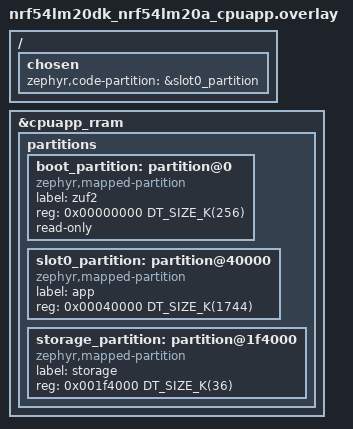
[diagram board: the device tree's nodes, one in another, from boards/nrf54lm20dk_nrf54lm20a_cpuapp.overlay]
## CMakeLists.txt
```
cmake_minimum_required(VERSION 3.20.0)

find_package(Zephyr REQUIRED HINTS $ENV{ZEPHYR_BASE})
project(zuf2_hello)

target_sources(app PRIVATE src/main.c)
```

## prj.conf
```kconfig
CONFIG_USE_DT_CODE_PARTITION=y
CONFIG_INIT_ARCH_HW_AT_BOOT=y
CONFIG_BOOT_BANNER=y

CONFIG_LOG=y
CONFIG_GPIO=y
CONFIG_MAIN_STACK_SIZE=2048
```

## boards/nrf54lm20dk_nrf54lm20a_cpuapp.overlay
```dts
/delete-node/ &boot_partition;
/delete-node/ &slot0_partition;
/delete-node/ &slot1_partition;
/delete-node/ &storage_partition;

/ {
	chosen {
		zephyr,code-partition = &slot0_partition;
	};
};

&cpuapp_rram {
	partitions {
		ranges;
		#address-cells = <1>;
		#size-cells = <1>;

		boot_partition: partition@0 {
			compatible = "zephyr,mapped-partition";
			label = "zuf2";
			reg = <0x00000000 DT_SIZE_K(256)>;
			read-only;
		};

		slot0_partition: partition@40000 {
			compatible = "zephyr,mapped-partition";
			label = "app";
			reg = <0x00040000 DT_SIZE_K(1744)>;
		};

		storage_partition: partition@1f4000 {
			compatible = "zephyr,mapped-partition";
			label = "storage";
			reg = <0x001f4000 DT_SIZE_K(36)>;
		};
	};
};
```

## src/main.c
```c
#include <zephyr/device.h>
#include <zephyr/devicetree.h>
#include <zephyr/drivers/gpio.h>
#include <zephyr/kernel.h>
#include <zephyr/logging/log.h>

LOG_MODULE_REGISTER(zuf2_hello, LOG_LEVEL_INF);

#if DT_NODE_HAS_STATUS(DT_ALIAS(led0), okay)
static const struct gpio_dt_spec led = GPIO_DT_SPEC_GET(DT_ALIAS(led0), gpios);
#define HAS_LED 1
#else
#define HAS_LED 0
#endif

int main(void)
{
	LOG_INF("zuf2 chain-loaded hello app");

#if HAS_LED
	if (!device_is_ready(led.port)) {
		LOG_ERR("LED device is not ready");
		return 0;
	}

	if (gpio_pin_configure_dt(&led, GPIO_OUTPUT_INACTIVE) != 0) {
		LOG_ERR("failed to configure LED");
		return 0;
	}

	while (true) {
		(void)gpio_pin_toggle_dt(&led);
		k_sleep(K_MSEC(500));
	}
#else
	while (true) {
		k_sleep(K_SECONDS(1));
	}
#endif
}
```
